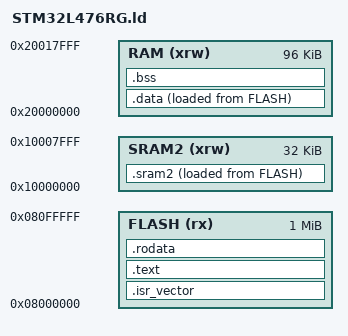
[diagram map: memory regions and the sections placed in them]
/*
******************************************************************************

******************************************************************************
*/

/* Entry Point */
ENTRY(Reset_Handler)

/* Highest address of the user mode stack */
_estack = ORIGIN(RAM) + LENGTH(RAM); /* end of "RAM" Ram type memory */

/* Memories definition */
MEMORY
{
  RAM    (xrw)    : ORIGIN = 0x20000000,   LENGTH = 96K
  SRAM2    (xrw)    : ORIGIN = 0x10000000,   LENGTH = 32K
  FLASH    (rx)    : ORIGIN = 0x8000000,   LENGTH = 1024K
}

/* Sections */
SECTIONS
{
  /* The startup code into "FLASH" Rom type memory */
  .isr_vector :
  {
    . = ALIGN(4);
    KEEP(*(.isr_vector)) /* Startup code */
    . = ALIGN(4);
  } >FLASH

  /* The program code and other data into "FLASH" Rom type memory */
  .text :
  {
    . = ALIGN(4);
    *(.text)           /* .text sections (code) */
    *(.text*)          /* .text* sections (code) */
    . = ALIGN(4);
    _etext = .;        /* define a global symbols at end of code */
  } >FLASH

  /* Constant data into "FLASH" Rom type memory */
  .rodata :
  {
    . = ALIGN(4);
    *(.rodata)         /* .rodata sections (constants, strings, etc.) */
    *(.rodata*)        /* .rodata* sections (constants, strings, etc.) */
    . = ALIGN(4);
  } >FLASH

  /* Used by the startup to initialize data */
  _sidata = LOADADDR(.data);

  /* Initialized data sections into "RAM" Ram type memory */
  .data :
  {
    . = ALIGN(4);
    _sdata = .;        /* create a global symbol at data start */
    *(.data)           /* .data sections */
    *(.data*)          /* .data* sections */
    . = ALIGN(4);
    _edata = .;        /* define a global symbol at data end */

  } >RAM AT> FLASH
 
  _sisram2 = LOADADDR(.sram2);

  /* SRAM2 section
  *
  * IMPORTANT NOTE!
  * If initialized variables will be placed in this section,
  * the startup code needs to be modified to copy the init-values.
  */
  .sram2 :
  {
    . = ALIGN(4);
    _ssram2 = .;       /* create a global symbol at sram2 start */
    *(.sram2)
    *(.sram2*)

    . = ALIGN(4);
    _esram2 = .;       /* create a global symbol at sram2 end */
  } >SRAM2 AT> FLASH
  
  /* Uninitialized data section into "RAM" Ram type memory */
  . = ALIGN(4);
  .bss :
  {
    /* This is used by the startup in order to initialize the .bss section */
    _sbss = .;         /* define a global symbol at bss start */
    *(.bss)
    *(.bss*)
    *(COMMON)
    . = ALIGN(4);
    _ebss = .;         /* define a global symbol at bss end */
  } >RAM

}
